AUTOSAR XML (schema 4-0-3)
standard types defined: Boolean, UInt32
package /AUTOSAR_Platform/DataConstrs
  range DC_Boolean: raw 0..1
package /PATAC/Facility/DataTypes/Implementation
  compu method COMPU_Boolean: 0=FALSE, 1=TRUE
  unit NoUnit: factor-si-to-unit=1, offset-si-to-unit=0
package /PATAC/MSM/ComponentTypes
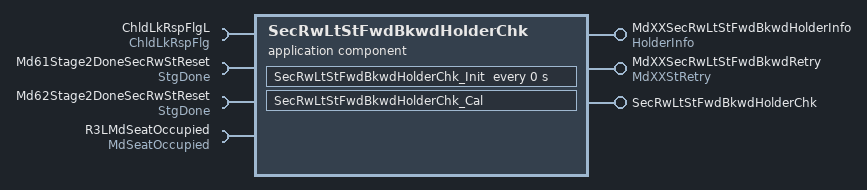
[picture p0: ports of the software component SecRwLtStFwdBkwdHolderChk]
  application sw component type SecRwLtStFwdBkwdHolderChk
    provide port MdXXSecRwLtStFwdBkwdHolderInfo: nonqueued-sender-com-spec{data-element=HolderInfo/Val, init-value=0}, provided-interface=HolderInfo
    provide port MdXXSecRwLtStFwdBkwdRetry: nonqueued-sender-com-spec{data-element=MdXXStRetry/Val, init-value=0}, provided-interface=MdXXStRetry
    provide port SecRwLtStFwdBkwdHolderChk: server-com-spec{operation=Cal, queue-length=1}, provided-interface=SecRwLtStFwdBkwdHolderChk
    4 x require port:
      ChldLkRspFlgL: nonqueued-receiver-com-spec{data-element=ChldLkRspFlg/Val, filter=data-filter-type=ALWAYS, init-value=0}, required-interface=ChldLkRspFlg
      Md61Stage2DoneSecRwStReset: nonqueued-receiver-com-spec{data-element=StgDone/Val, filter=data-filter-type=ALWAYS, init-value=0}, required-interface=StgDone
      Md62Stage2DoneSecRwStReset: nonqueued-receiver-com-spec{data-element=StgDone/Val, filter=data-filter-type=ALWAYS, init-value=0}, required-interface=StgDone
      R3LMdSeatOccupied: nonqueued-receiver-com-spec{data-element=MdSeatOccupied/Val, filter=data-filter-type=ALWAYS, init-value=0}, required-interface=MdSeatOccupied
    behavior SecRwLtStFwdBkwdHolderChk_InternalBehavior
      operation invoked event OIT_SecRwLtStFwdBkwdHolderChk_Cal_SecRwLtStFwdBkwdHolderChk_Cal: start-on-event=SecRwLtStFwdBkwdHolderChk_Cal, operation=SecRwLtStFwdBkwdHolderChk.Cal
      timing event SecRwLtStFwdBkwdHolderChk_InitEvent: start-on-event=SecRwLtStFwdBkwdHolderChk_Init, period=0
      runnable SecRwLtStFwdBkwdHolderChk_Cal
        data-receive-point-by-arguments:
          4 x access:
            REC_ChldLkRspFlgL_Val: accessed-variable=ChldLkRspFlgL.Val
            REC_Md61Stage2DoneSecRwStReset_Val: accessed-variable=Md61Stage2DoneSecRwStReset.Val
            REC_Md62Stage2DoneSecRwStReset_Val: accessed-variable=Md62Stage2DoneSecRwStReset.Val
            REC_R3LMdSeatOccupied_Val: accessed-variable=R3LMdSeatOccupied.Val
        data-send-points:
          access SEND_MdXXSecRwLtStFwdBkwdHolderInfo_Val: accessed-variable=MdXXSecRwLtStFwdBkwdHolderInfo.Val
          access SEND_MdXXSecRwLtStFwdBkwdRetry_Val: accessed-variable=MdXXSecRwLtStFwdBkwdRetry.Val
      runnable SecRwLtStFwdBkwdHolderChk_Init
  swc implementation SecRwLtStFwdBkwdHolderChk_Implementation: behavior=SecRwLtStFwdBkwdHolderChk_InternalBehavior
    code-descriptors:
      code Default: artifact-descriptors=autosar-engineering-object={short-label=Default, category=SWSRC}
package /PATAC/MSM/ModeAdjust/PortInterface
  client server interface SecRwLtStFwdBkwdHolderChk
    operation Cal
  5 x sender receiver interface:
    ChldLkRspFlg: invalidation-policy{data-element=ChldLkRspFlg/Val, handle-invalid=DONT-INVALIDATE}
      data Val: type=Boolean
    HolderInfo: invalidation-policy{data-element=HolderInfo/Val, handle-invalid=DONT-INVALIDATE}
      data Val: type=UInt32
    MdSeatOccupied: invalidation-policy{data-element=MdSeatOccupied/Val, handle-invalid=DONT-INVALIDATE}
      data Val: type=Boolean
    MdXXStRetry: invalidation-policy{data-element=MdXXStRetry/Val, handle-invalid=DONT-INVALIDATE}
      data Val: type=UInt32
    StgDone: invalidation-policy{data-element=StgDone/Val, handle-invalid=DONT-INVALIDATE}
      data Val: type=Boolean
